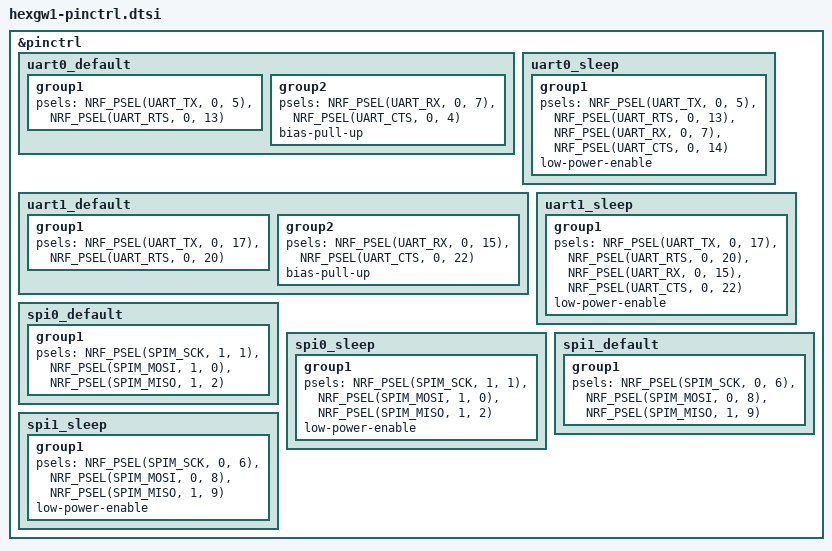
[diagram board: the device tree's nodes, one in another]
/*
 * Copyright (c) 2022 Nordic Semiconductor
 * SPDX-License-Identifier: Apache-2.0
 */

&pinctrl {
	uart0_default: uart0_default {
		group1 {
			psels = <NRF_PSEL(UART_TX, 0, 5)>,
				<NRF_PSEL(UART_RTS, 0, 13)>;
		};
		group2 {
			psels = <NRF_PSEL(UART_RX, 0, 7)>,
				<NRF_PSEL(UART_CTS, 0, 4)>;
			bias-pull-up;
		};
	};

	uart0_sleep: uart0_sleep {
		group1 {
			psels = <NRF_PSEL(UART_TX, 0, 5)>,
				<NRF_PSEL(UART_RTS, 0, 13)>,
				<NRF_PSEL(UART_RX, 0, 7)>,
				<NRF_PSEL(UART_CTS, 0, 14)>;
			low-power-enable;
		};
	};

	uart1_default: uart1_default {
		group1 {
			psels = <NRF_PSEL(UART_TX, 0, 17)>,
				<NRF_PSEL(UART_RTS, 0, 20)>;
		};
		group2 {
			psels = <NRF_PSEL(UART_RX, 0, 15)>,
				<NRF_PSEL(UART_CTS, 0, 22)>;
			bias-pull-up;
		};
	};

	uart1_sleep: uart1_sleep {
		group1 {
			psels = <NRF_PSEL(UART_TX, 0, 17)>,
				<NRF_PSEL(UART_RTS, 0, 20)>,
				<NRF_PSEL(UART_RX, 0, 15)>,
				<NRF_PSEL(UART_CTS, 0, 22)>;
			low-power-enable;
		};
	};

	spi0_default: spi0_default {
		group1 {
			psels = <NRF_PSEL(SPIM_SCK, 1, 1)>,
				<NRF_PSEL(SPIM_MOSI, 1, 0)>,
				<NRF_PSEL(SPIM_MISO, 1, 2)>;
		};
	};

	spi0_sleep: spi0_sleep {
		group1 {
			psels = <NRF_PSEL(SPIM_SCK, 1, 1)>,
				<NRF_PSEL(SPIM_MOSI, 1, 0)>,
				<NRF_PSEL(SPIM_MISO, 1, 2)>;
			low-power-enable;
		};
	};

	spi1_default: spi1_default {
		group1 {
			psels = <NRF_PSEL(SPIM_SCK, 0, 6)>,
				<NRF_PSEL(SPIM_MOSI, 0, 8)>,
				<NRF_PSEL(SPIM_MISO, 1, 9)>;
		};
	};

	spi1_sleep: spi1_sleep {
		group1 {
			psels = <NRF_PSEL(SPIM_SCK, 0, 6)>,
				<NRF_PSEL(SPIM_MOSI, 0, 8)>,
				<NRF_PSEL(SPIM_MISO, 1, 9)>;
			low-power-enable;
		};
	};
};
